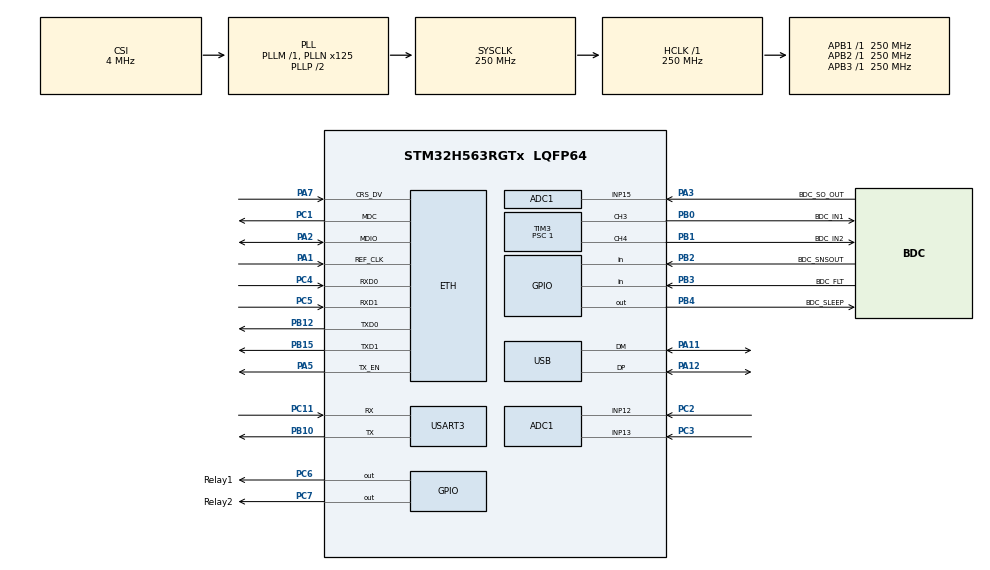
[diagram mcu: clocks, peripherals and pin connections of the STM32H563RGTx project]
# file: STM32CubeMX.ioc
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ADC1.ContinuousConvMode=DISABLE
ADC1.EOCSelection=ADC_EOC_SINGLE_CONV
ADC1.EnableRegularConversion=DISABLE
ADC1.master=1
BOOTPATH.BootPathName=LEGACY
BOOTPATH.UserSelectedBootPath=LEGACY
CORTEX_M33_NS.userName=CORTEX_M33
ETH.MediaInterface=HAL_ETH_RMII_MODE
FLASH.EDATA1size=1
FLASH.EDATA2size=1
FLASH.OB_EDATA1_active=true
FLASH.OB_EDATA2_active=true
Mcu.Family=STM32H5
Mcu.Name=STM32H563RGTx
Mcu.Package=LQFP64
NVIC.PriorityGroup=NVIC_PRIORITYGROUP_4
PA1.Mode=RMII
PA1.Signal=ETH_REF_CLK
PA11.Mode=Device
PA11.Signal=USB_DM
PA12.Mode=Device
PA12.Signal=USB_DP
PA13(JTMS/SWDIO).Mode=Serial_Wire
PA13(JTMS/SWDIO).Signal=DEBUG_JTMS-SWDIO
PA14(JTCK/SWCLK).Mode=Serial_Wire
PA14(JTCK/SWCLK).Signal=DEBUG_JTCK-SWCLK
PA2.Mode=RMII
PA2.Signal=ETH_MDIO
PA3.GPIO_Label=BDC_SO_OUT
PA3.Signal=ADCx_INP15
PA5.Mode=RMII
PA5.Signal=ETH_TX_EN
PA7.Mode=RMII
PA7.Signal=ETH_CRS_DV
PB0.GPIO_Label=BDC_IN1
PB0.Signal=S_TIM3_CH3
PB1.GPIO_Label=BDC_IN2
PB1.Signal=S_TIM3_CH4
PB10.Mode=Asynchronous
PB10.Signal=USART3_TX
PB12.Mode=RMII
PB12.Signal=ETH_TXD0
PB15.Mode=RMII
PB15.Signal=ETH_TXD1
PB2.GPIO_Label=BDC_SNSOUT
PB2.Signal=GPIO_Input
PB3(JTDO/TRACESWO).GPIO_Label=BDC_FLT
PB3(JTDO/TRACESWO).Signal=GPIO_Input
PB4(NJTRST).GPIO_Label=BDC_SLEEP
PB4(NJTRST).Signal=GPIO_Output
PC1.Mode=RMII
PC1.Signal=ETH_MDC
PC11.Mode=Asynchronous
PC11.Signal=USART3_RX
PC2.Signal=ADCx_INP12
PC3.Signal=ADCx_INP13
PC4.Mode=RMII
PC4.Signal=ETH_RXD0
PC5.Mode=RMII
PC5.Signal=ETH_RXD1
PC6.GPIO_Label=Relay1
PC6.Signal=GPIO_Output
PC7.GPIO_Label=Relay2
PC7.Signal=GPIO_Output
ProjectManager.HeapSize=0x200
ProjectManager.StackSize=0x400
ProjectManager.TargetToolchain=MDK-ARM V5
RCC.ADCCLockSelection=RCC_ADCDACCLKSOURCE_HSI
RCC.ADCFreq_Value=32000000
RCC.AHBFreq_Value=250000000
RCC.APB1Freq_Value=250000000
RCC.APB1TimFreq_Value=250000000
RCC.APB2Freq_Value=250000000
RCC.APB2TimFreq_Value=250000000
RCC.APB3Freq_Value=250000000
RCC.CSI_VALUE=4000000
RCC.CortexFreq_Value=250000000
RCC.EPOD_VALUE=4000000
RCC.HCLKFreq_Value=250000000
RCC.HSE_VALUE=25000000
RCC.HSI48_VALUE=48000000
RCC.HSI_VALUE=64000000
RCC.LSE_VALUE=32768
RCC.LSIRC_VALUE=32000
RCC.PLLFRACN=0
RCC.PLLN=125
RCC.SYSCLKFreq_VALUE=250000000
RCC.SYSCLKSource=RCC_SYSCLKSOURCE_PLLCLK
RCC.USBFreq_Value=48000000
RCC.VCOOutputFreq_Value=500000000
SH.ADCx_INP12.0=ADC1_INP12,IN12-Single-Ended
SH.ADCx_INP13.0=ADC1_INP13,IN13-Single-Ended
SH.ADCx_INP15.0=ADC1_INP15,IN15-Single-Ended
SH.S_TIM3_CH3.0=TIM3_CH3,PWM Generation3 CH3
SH.S_TIM3_CH4.0=TIM3_CH4,PWM Generation4 CH4
TIM3.AutoReloadPreload=TIM_AUTORELOAD_PRELOAD_ENABLE
TIM3.Channel-PWM\ Generation3\ CH3=TIM_CHANNEL_3
TIM3.Channel-PWM\ Generation4\ CH4=TIM_CHANNEL_4
TIM3.PeriodNoDither=10000
TIM3.Prescaler=1
USART3.VirtualMode-Asynchronous=VM_ASYNC
USB.VirtualMode=Device_Only
VP_BOOTPATH_VS_BOOTPATH.Mode=BP_Activate
VP_CORTEX_M33_NS_VS_Hclk.Mode=Hclk_Mode
VP_FLASH_SIG_Activate_FlashIP.Mode=Activate_FlashIP
VP_ICACHE_VS_ICACHE.Mode=DirectMappedCache
VP_MEMORYMAP_VS_MEMORYMAP.Mode=CurAppReg
VP_PWR_VS_DBSignals.Mode=DisableDeadBatterySignals
VP_PWR_VS_LPOM.Mode=PowerOptimisation
VP_PWR_VS_SECSignals.Mode=Security/Privilege
board=custom

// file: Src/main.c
/* USER CODE BEGIN Header */
/**
  ******************************************************************************
  * @file           : main.c
  * @brief          : Main program body
  ******************************************************************************
  * @attention
  *
  * Copyright (c) 2024 STMicroelectronics.
  * All rights reserved.
  *
  * This software is licensed under terms that can be found in the LICENSE file
  * in the root directory of this software component.
  * If no LICENSE file comes with this software, it is provided AS-IS.
  *
  ******************************************************************************
  */
/* USER CODE END Header */
#include "main.h"
#include "string.h"

ETH_TxPacketConfigTypeDef TxConfig;
ETH_DMADescTypeDef  DMARxDscrTab[ETH_RX_DESC_CNT]; /* Ethernet Rx DMA Descriptors */
ETH_DMADescTypeDef  DMATxDscrTab[ETH_TX_DESC_CNT]; /* Ethernet Tx DMA Descriptors */

ADC_HandleTypeDef hadc1;

ETH_HandleTypeDef heth;

TIM_HandleTypeDef htim3;

UART_HandleTypeDef huart3;

PCD_HandleTypeDef hpcd_USB_DRD_FS;

/* USER CODE BEGIN PV */
extern void rtx_init (void);
// testing -----------------------------------------------------------------
extern void test_flash(void);

/* USER CODE END PV */

void SystemClock_Config(void);
static void MX_GPIO_Init(void);
static void MX_ETH_Init(void);
static void MX_ICACHE_Init(void);
static void MX_USART3_UART_Init(void);
static void MX_ADC1_Init(void);
static void MX_USB_PCD_Init(void);
static void MX_TIM3_Init(void);
static void MX_FLASH_Init(void);

int main(void)
{

  /* MCU Configuration--------------------------------------------------------*/

  /* Reset of all peripherals, Initializes the Flash interface and the Systick. */
  HAL_Init();

  /* Configure the system clock */
  SystemClock_Config();

  /* Initialize all configured peripherals */
  MX_GPIO_Init();
  MX_ETH_Init();
  MX_ICACHE_Init();
  MX_USART3_UART_Init();
  MX_ADC1_Init();
  MX_USB_PCD_Init();
  MX_TIM3_Init();
  MX_FLASH_Init();
  /* USER CODE BEGIN 2 */

	rtx_init();
  /* USER CODE END 2 */

  /* Infinite loop */
  while (1)
  {

  }
}

void SystemClock_Config(void)
{
  RCC_OscInitTypeDef RCC_OscInitStruct = {0};
  RCC_ClkInitTypeDef RCC_ClkInitStruct = {0};

  /** Configure the main internal regulator output voltage
  */
  __HAL_PWR_VOLTAGESCALING_CONFIG(PWR_REGULATOR_VOLTAGE_SCALE0);

  while(!__HAL_PWR_GET_FLAG(PWR_FLAG_VOSRDY)) {}

  /** Initializes the RCC Oscillators according to the specified parameters
  * in the RCC_OscInitTypeDef structure.
  */
  RCC_OscInitStruct.OscillatorType = RCC_OSCILLATORTYPE_HSI48|RCC_OSCILLATORTYPE_HSI
                              |RCC_OSCILLATORTYPE_CSI;
  RCC_OscInitStruct.HSIState = RCC_HSI_ON;
  RCC_OscInitStruct.HSIDiv = RCC_HSI_DIV2;
  RCC_OscInitStruct.HSICalibrationValue = RCC_HSICALIBRATION_DEFAULT;
  RCC_OscInitStruct.HSI48State = RCC_HSI48_ON;
  RCC_OscInitStruct.CSIState = RCC_CSI_ON;
  RCC_OscInitStruct.CSICalibrationValue = RCC_CSICALIBRATION_DEFAULT;
  RCC_OscInitStruct.PLL.PLLState = RCC_PLL_ON;
  RCC_OscInitStruct.PLL.PLLSource = RCC_PLL1_SOURCE_CSI;
  RCC_OscInitStruct.PLL.PLLM = 1;
  RCC_OscInitStruct.PLL.PLLN = 125;
  RCC_OscInitStruct.PLL.PLLP = 2;
  RCC_OscInitStruct.PLL.PLLQ = 2;
  RCC_OscInitStruct.PLL.PLLR = 2;
  RCC_OscInitStruct.PLL.PLLRGE = RCC_PLL1_VCIRANGE_2;
  RCC_OscInitStruct.PLL.PLLVCOSEL = RCC_PLL1_VCORANGE_WIDE;
  RCC_OscInitStruct.PLL.PLLFRACN = 0;
  if (HAL_RCC_OscConfig(&RCC_OscInitStruct) != HAL_OK)
  {
    Error_Handler();
  }

  /** Initializes the CPU, AHB and APB buses clocks
  */
  RCC_ClkInitStruct.ClockType = RCC_CLOCKTYPE_HCLK|RCC_CLOCKTYPE_SYSCLK
                              |RCC_CLOCKTYPE_PCLK1|RCC_CLOCKTYPE_PCLK2
                              |RCC_CLOCKTYPE_PCLK3;
  RCC_ClkInitStruct.SYSCLKSource = RCC_SYSCLKSOURCE_PLLCLK;
  RCC_ClkInitStruct.AHBCLKDivider = RCC_SYSCLK_DIV1;
  RCC_ClkInitStruct.APB1CLKDivider = RCC_HCLK_DIV1;
  RCC_ClkInitStruct.APB2CLKDivider = RCC_HCLK_DIV1;
  RCC_ClkInitStruct.APB3CLKDivider = RCC_HCLK_DIV1;

  if (HAL_RCC_ClockConfig(&RCC_ClkInitStruct, FLASH_LATENCY_5) != HAL_OK)
  {
    Error_Handler();
  }

  /** Configure the programming delay
  */
  __HAL_FLASH_SET_PROGRAM_DELAY(FLASH_PROGRAMMING_DELAY_2);
}

static void MX_ADC1_Init(void)
{

  /** Common config
  */
  hadc1.Instance = ADC1;
  hadc1.Init.ClockPrescaler = ADC_CLOCK_ASYNC_DIV1;
  hadc1.Init.Resolution = ADC_RESOLUTION_12B;
  hadc1.Init.DataAlign = ADC_DATAALIGN_RIGHT;
  hadc1.Init.ScanConvMode = ADC_SCAN_DISABLE;
  hadc1.Init.EOCSelection = ADC_EOC_SINGLE_CONV;
  hadc1.Init.LowPowerAutoWait = DISABLE;
  hadc1.Init.ContinuousConvMode = DISABLE;
  hadc1.Init.NbrOfConversion = 1;
  hadc1.Init.DiscontinuousConvMode = DISABLE;
  hadc1.Init.DMAContinuousRequests = DISABLE;
  hadc1.Init.SamplingMode = ADC_SAMPLING_MODE_NORMAL;
  hadc1.Init.Overrun = ADC_OVR_DATA_PRESERVED;
  hadc1.Init.OversamplingMode = DISABLE;
  if (HAL_ADC_Init(&hadc1) != HAL_OK)
  {
    Error_Handler();
  }

}

static void MX_ETH_Init(void)
{

   static uint8_t MACAddr[6];

  heth.Instance = ETH;
  MACAddr[0] = 0x00;
  MACAddr[1] = 0x80;
  MACAddr[2] = 0xE1;
  MACAddr[3] = 0x00;
  MACAddr[4] = 0x00;
  MACAddr[5] = 0x00;
  heth.Init.MACAddr = &MACAddr[0];
  heth.Init.MediaInterface = HAL_ETH_RMII_MODE;
  heth.Init.TxDesc = DMATxDscrTab;
  heth.Init.RxDesc = DMARxDscrTab;
  heth.Init.RxBuffLen = 1524;

  if (HAL_ETH_Init(&heth) != HAL_OK)
  {
    Error_Handler();
  }

  memset(&TxConfig, 0 , sizeof(ETH_TxPacketConfigTypeDef));
  TxConfig.Attributes = ETH_TX_PACKETS_FEATURES_CSUM | ETH_TX_PACKETS_FEATURES_CRCPAD;
  TxConfig.ChecksumCtrl = ETH_CHECKSUM_IPHDR_PAYLOAD_INSERT_PHDR_CALC;
  TxConfig.CRCPadCtrl = ETH_CRC_PAD_INSERT;

}

static void MX_FLASH_Init(void)
{

  FLASH_OBProgramInitTypeDef pOBInit = {0};

  if (HAL_FLASH_Unlock() != HAL_OK)
  {
    Error_Handler();
  }

  /* Option Bytes settings */

  if (HAL_FLASH_OB_Unlock() != HAL_OK)
  {
    Error_Handler();
  }
  pOBInit.OptionType = OPTIONBYTE_EDATA;
  pOBInit.Banks = FLASH_BANK_BOTH;
  pOBInit.EDATASize = 1;
  if (HAL_FLASHEx_OBProgram(&pOBInit) != HAL_OK)
  {
    Error_Handler();
  }
  if (HAL_FLASH_OB_Lock() != HAL_OK)
  {
    Error_Handler();
  }
  if (HAL_FLASH_Lock() != HAL_OK)
  {
    Error_Handler();
  }

  /* Launch Option Bytes Loading */
  /*HAL_FLASH_OB_Launch(); */

}

static void MX_ICACHE_Init(void)
{

  /** Enable instruction cache in 1-way (direct mapped cache)
  */
  if (HAL_ICACHE_ConfigAssociativityMode(ICACHE_1WAY) != HAL_OK)
  {
    Error_Handler();
  }
  if (HAL_ICACHE_Enable() != HAL_OK)
  {
    Error_Handler();
  }

}

static void MX_TIM3_Init(void)
{

  TIM_MasterConfigTypeDef sMasterConfig = {0};
  TIM_OC_InitTypeDef sConfigOC = {0};

  htim3.Instance = TIM3;
  htim3.Init.Prescaler = 1;
  htim3.Init.CounterMode = TIM_COUNTERMODE_UP;
  htim3.Init.Period = 10000;
  htim3.Init.ClockDivision = TIM_CLOCKDIVISION_DIV1;
  htim3.Init.AutoReloadPreload = TIM_AUTORELOAD_PRELOAD_ENABLE;
  if (HAL_TIM_PWM_Init(&htim3) != HAL_OK)
  {
    Error_Handler();
  }
  sMasterConfig.MasterOutputTrigger = TIM_TRGO_RESET;
  sMasterConfig.MasterSlaveMode = TIM_MASTERSLAVEMODE_DISABLE;
  if (HAL_TIMEx_MasterConfigSynchronization(&htim3, &sMasterConfig) != HAL_OK)
  {
    Error_Handler();
  }
  sConfigOC.OCMode = TIM_OCMODE_PWM1;
  sConfigOC.Pulse = 0;
  sConfigOC.OCPolarity = TIM_OCPOLARITY_HIGH;
  sConfigOC.OCFastMode = TIM_OCFAST_DISABLE;
  if (HAL_TIM_PWM_ConfigChannel(&htim3, &sConfigOC, TIM_CHANNEL_3) != HAL_OK)
  {
    Error_Handler();
  }
  if (HAL_TIM_PWM_ConfigChannel(&htim3, &sConfigOC, TIM_CHANNEL_4) != HAL_OK)
  {
    Error_Handler();
  }
  HAL_TIM_MspPostInit(&htim3);

}

static void MX_USART3_UART_Init(void)
{

  huart3.Instance = USART3;
  huart3.Init.BaudRate = 115200;
  huart3.Init.WordLength = UART_WORDLENGTH_8B;
  huart3.Init.StopBits = UART_STOPBITS_1;
  huart3.Init.Parity = UART_PARITY_NONE;
  huart3.Init.Mode = UART_MODE_TX_RX;
  huart3.Init.HwFlowCtl = UART_HWCONTROL_NONE;
  huart3.Init.OverSampling = UART_OVERSAMPLING_16;
  huart3.Init.OneBitSampling = UART_ONE_BIT_SAMPLE_DISABLE;
  huart3.Init.ClockPrescaler = UART_PRESCALER_DIV1;
  huart3.AdvancedInit.AdvFeatureInit = UART_ADVFEATURE_NO_INIT;
  if (HAL_UART_Init(&huart3) != HAL_OK)
  {
    Error_Handler();
  }
  if (HAL_UARTEx_SetTxFifoThreshold(&huart3, UART_TXFIFO_THRESHOLD_1_8) != HAL_OK)
  {
    Error_Handler();
  }
  if (HAL_UARTEx_SetRxFifoThreshold(&huart3, UART_RXFIFO_THRESHOLD_1_8) != HAL_OK)
  {
    Error_Handler();
  }
  if (HAL_UARTEx_DisableFifoMode(&huart3) != HAL_OK)
  {
    Error_Handler();
  }

}

static void MX_USB_PCD_Init(void)
{

  hpcd_USB_DRD_FS.Instance = USB_DRD_FS;
  hpcd_USB_DRD_FS.Init.dev_endpoints = 8;
  hpcd_USB_DRD_FS.Init.speed = USBD_FS_SPEED;
  hpcd_USB_DRD_FS.Init.phy_itface = PCD_PHY_EMBEDDED;
  hpcd_USB_DRD_FS.Init.Sof_enable = DISABLE;
  hpcd_USB_DRD_FS.Init.low_power_enable = DISABLE;
  hpcd_USB_DRD_FS.Init.lpm_enable = DISABLE;
  hpcd_USB_DRD_FS.Init.battery_charging_enable = DISABLE;
  hpcd_USB_DRD_FS.Init.vbus_sensing_enable = DISABLE;
  hpcd_USB_DRD_FS.Init.bulk_doublebuffer_enable = DISABLE;
  hpcd_USB_DRD_FS.Init.iso_singlebuffer_enable = DISABLE;
  if (HAL_PCD_Init(&hpcd_USB_DRD_FS) != HAL_OK)
  {
    Error_Handler();
  }

}

static void MX_GPIO_Init(void)
{
  GPIO_InitTypeDef GPIO_InitStruct = {0};

  /* GPIO Ports Clock Enable */
  __HAL_RCC_GPIOC_CLK_ENABLE();
  __HAL_RCC_GPIOA_CLK_ENABLE();
  __HAL_RCC_GPIOB_CLK_ENABLE();

  /*Configure GPIO pin Output Level */
  HAL_GPIO_WritePin(GPIOC, Relay1_Pin|Relay2_Pin, GPIO_PIN_RESET);

  /*Configure GPIO pin Output Level */
  HAL_GPIO_WritePin(BDC_SLEEP_GPIO_Port, BDC_SLEEP_Pin, GPIO_PIN_RESET);

  /*Configure GPIO pins : BDC_SNSOUT_Pin BDC_FLT_Pin */
  GPIO_InitStruct.Pin = BDC_SNSOUT_Pin|BDC_FLT_Pin;
  GPIO_InitStruct.Mode = GPIO_MODE_INPUT;
  GPIO_InitStruct.Pull = GPIO_NOPULL;
  HAL_GPIO_Init(GPIOB, &GPIO_InitStruct);

  /*Configure GPIO pins : Relay1_Pin Relay2_Pin */
  GPIO_InitStruct.Pin = Relay1_Pin|Relay2_Pin;
  GPIO_InitStruct.Mode = GPIO_MODE_OUTPUT_PP;
  GPIO_InitStruct.Pull = GPIO_NOPULL;
  GPIO_InitStruct.Speed = GPIO_SPEED_FREQ_LOW;
  HAL_GPIO_Init(GPIOC, &GPIO_InitStruct);

  /*Configure GPIO pin : BDC_SLEEP_Pin */
  GPIO_InitStruct.Pin = BDC_SLEEP_Pin;
  GPIO_InitStruct.Mode = GPIO_MODE_OUTPUT_PP;
  GPIO_InitStruct.Pull = GPIO_NOPULL;
  GPIO_InitStruct.Speed = GPIO_SPEED_FREQ_LOW;
  HAL_GPIO_Init(BDC_SLEEP_GPIO_Port, &GPIO_InitStruct);

}

void Error_Handler(void)
{
  __disable_irq();
  while (1)
  {
  }
}
